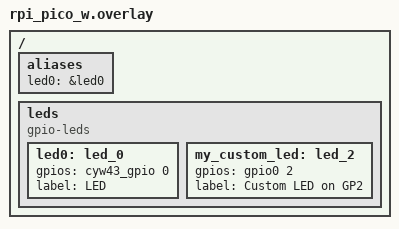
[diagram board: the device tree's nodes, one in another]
/ {
    aliases {
        led0 = &led0;
    };

    leds {
        compatible = "gpio-leds";

        led0: led_0 {
			gpios = <&cyw43_gpio 0 GPIO_ACTIVE_HIGH>;
			label = "LED";
		};

        my_custom_led: led_2 {
            /* Map to GP2 on the RP2040 (gpio0 is the main GPIO controller) */
            gpios = <&gpio0 2 GPIO_ACTIVE_HIGH>;
            label = "Custom LED on GP2";
        };
    };
};
